VERSION ""

NS_ :

BS_:

BU_:

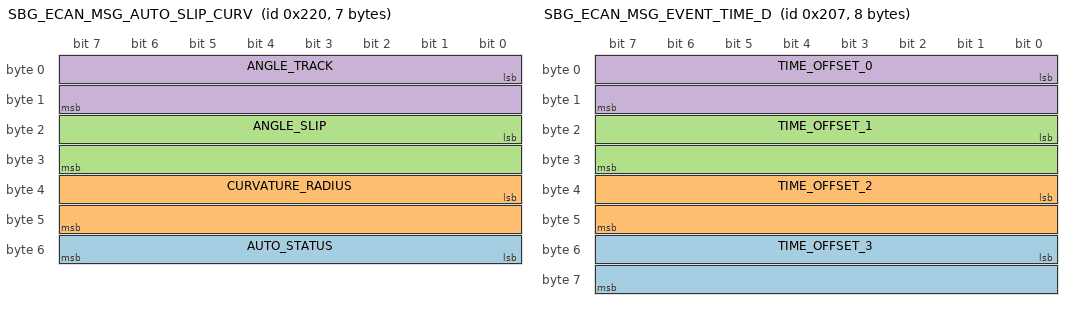
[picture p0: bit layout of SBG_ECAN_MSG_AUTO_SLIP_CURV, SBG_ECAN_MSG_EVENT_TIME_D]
BO_ 544 SBG_ECAN_MSG_AUTO_SLIP_CURV: 7 Vector__XXX
 SG_ AUTO_STATUS : 48|8@1+ (1,0) [0|255] "" Vector__XXX
 SG_ CURVATURE_RADIUS : 32|16@1+ (0.01,0) [0|655.35] "m" Vector__XXX
 SG_ ANGLE_SLIP : 16|16@1- (0.0001,0) [-3.2768|3.2767] "rad" Vector__XXX
 SG_ ANGLE_TRACK : 0|16@1- (0.0001,0) [-3.2768|3.2767] "rad" Vector__XXX

BO_ 519 SBG_ECAN_MSG_EVENT_TIME_D: 8 Vector__XXX
 SG_ TIME_OFFSET_3 : 48|16@1+ (1,0) [0|65535] "µs" Vector__XXX
 SG_ TIME_OFFSET_2 : 32|16@1+ (1,0) [0|65535] "µs" Vector__XXX
 SG_ TIME_OFFSET_1 : 16|16@1+ (1,0) [0|65535] "µs" Vector__XXX
 SG_ TIME_OFFSET_0 : 0|16@1+ (1,0) [0|65535] "µs" Vector__XXX

BO_ 518 SBG_ECAN_MSG_EVENT_INFO_D: 8 Vector__XXX
 SG_ EVENT_STATUS : 32|16@1+ (1,0) [0|65535] "" Vector__XXX
 SG_ TIME_STAMP : 0|32@1+ (1,0) [0|4294970000] "µs" Vector__XXX

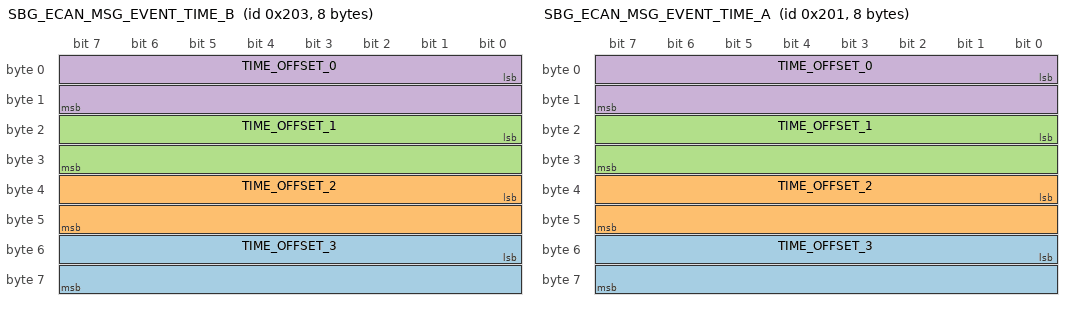
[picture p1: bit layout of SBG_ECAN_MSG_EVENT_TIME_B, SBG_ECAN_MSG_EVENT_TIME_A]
BO_ 515 SBG_ECAN_MSG_EVENT_TIME_B: 8 Vector__XXX
 SG_ TIME_OFFSET_3 : 48|16@1+ (1,0) [0|65535] "µs" Vector__XXX
 SG_ TIME_OFFSET_2 : 32|16@1+ (1,0) [0|65535] "µs" Vector__XXX
 SG_ TIME_OFFSET_1 : 16|16@1+ (1,0) [0|65535] "µs" Vector__XXX
 SG_ TIME_OFFSET_0 : 0|16@1+ (1,0) [0|65535] "µs" Vector__XXX

BO_ 514 SBG_ECAN_MSG_EVENT_INFO_B: 8 Vector__XXX
 SG_ EVENT_STATUS : 32|16@1+ (1,0) [0|65535] "" Vector__XXX
 SG_ TIME_STAMP : 0|32@1+ (1,0) [0|4294970000] "µs" Vector__XXX

BO_ 513 SBG_ECAN_MSG_EVENT_TIME_A: 8 Vector__XXX
 SG_ TIME_OFFSET_3 : 48|16@1+ (1,0) [0|65535] "µs" Vector__XXX
 SG_ TIME_OFFSET_2 : 32|16@1+ (1,0) [0|65535] "µs" Vector__XXX
 SG_ TIME_OFFSET_1 : 16|16@1+ (1,0) [0|65535] "µs" Vector__XXX
 SG_ TIME_OFFSET_0 : 0|16@1+ (1,0) [0|65535] "µs" Vector__XXX

BO_ 512 SBG_ECAN_MSG_EVENT_INFO_A: 8 Vector__XXX
 SG_ EVENT_STATUS : 32|16@1+ (1,0) [0|65535] "" Vector__XXX
 SG_ TIME_STAMP : 0|32@1+ (1,0) [0|4294970000] "µs" Vector__XXX

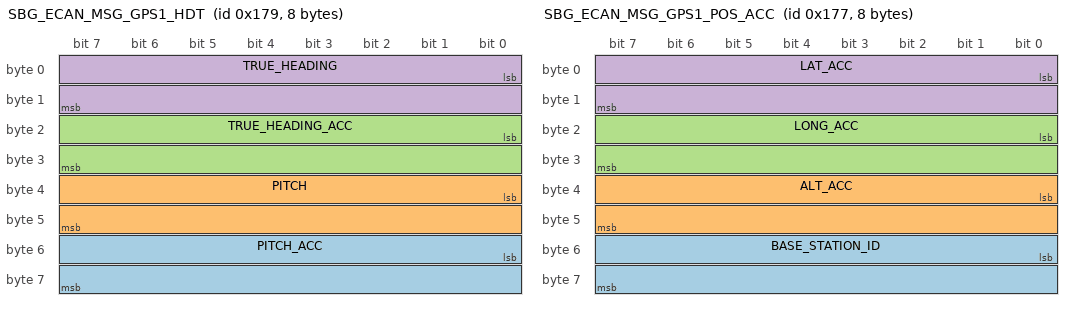
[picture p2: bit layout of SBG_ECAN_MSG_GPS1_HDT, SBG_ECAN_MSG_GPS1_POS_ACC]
BO_ 377 SBG_ECAN_MSG_GPS1_HDT: 8 Vector__XXX
 SG_ PITCH_ACC : 48|16@1+ (0.01,0) [0|655.35] "°" Vector__XXX
 SG_ PITCH : 32|16@1- (0.01,0) [-327.68|327.67] "°" Vector__XXX
 SG_ TRUE_HEADING_ACC : 16|16@1+ (0.01,0) [0|655.35] "°" Vector__XXX
 SG_ TRUE_HEADING : 0|16@1+ (0.01,0) [0|655.35] "°" Vector__XXX

BO_ 376 SBG_ECAN_MSG_GPS1_HDT_INFO: 6 Vector__XXX
 SG_ GPS_HDT_STATUS : 32|16@1+ (1,0) [0|65535] "" Vector__XXX
 SG_ TIME_STAMP : 0|32@1+ (1,0) [0|4294970000] "µs" Vector__XXX

BO_ 375 SBG_ECAN_MSG_GPS1_POS_ACC: 8 Vector__XXX
 SG_ BASE_STATION_ID : 48|16@1+ (1,0) [0|65535] "" Vector__XXX
 SG_ ALT_ACC : 32|16@1+ (0.01,0) [0|655.35] "m" Vector__XXX
 SG_ LONG_ACC : 16|16@1+ (0.01,0) [0|655.35] "m" Vector__XXX
 SG_ LAT_ACC : 0|16@1+ (0.01,0) [0|655.35] "m" Vector__XXX

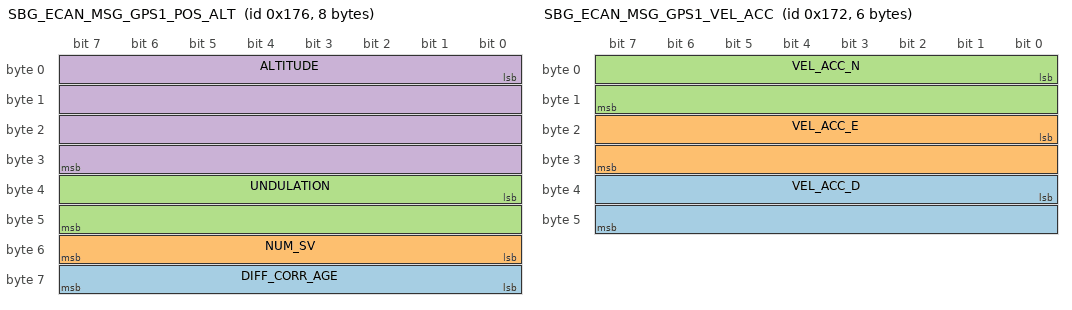
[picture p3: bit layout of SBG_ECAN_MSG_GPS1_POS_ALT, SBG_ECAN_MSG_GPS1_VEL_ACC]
BO_ 374 SBG_ECAN_MSG_GPS1_POS_ALT: 8 Vector__XXX
 SG_ DIFF_CORR_AGE : 56|8@1+ (1,7) [7|262] "s" Vector__XXX
 SG_ NUM_SV : 48|8@1+ (1,48) [48|303] "" Vector__XXX
 SG_ UNDULATION : 32|16@1- (0.005,0) [-163.84|163.835] "m" Vector__XXX
 SG_ ALTITUDE : 0|32@1- (0.001,0) [-2147480|2147480] "m" Vector__XXX

BO_ 373 SBG_ECAN_MSG_GPS1_POS: 8 Vector__XXX
 SG_ LONGITUDE : 32|32@1- (1E-007,0) [-214.7483648|214.7483647] "°" Vector__XXX
 SG_ LATITUDE : 0|32@1- (1E-007,0) [-214.7483648|214.7483647] "°" Vector__XXX

BO_ 372 SBG_ECAN_MSG_GPS1_POS_INFO: 8 Vector__XXX
 SG_ GPS_POS_STATUS : 32|32@1+ (1,0) [0|4294970000] "" Vector__XXX
 SG_ TIME_STAMP : 0|32@1+ (1,0) [0|4294970000] "µs" Vector__XXX

BO_ 371 SBG_ECAN_MSG_GPS1_VEL_COURSE: 4 Vector__XXX
 SG_ COURSE_ACC : 16|16@1+ (0.01,0) [0|655.35] "°" Vector__XXX
 SG_ COURSE : 0|16@1+ (0.01,0) [0|655.35] "°" Vector__XXX

BO_ 370 SBG_ECAN_MSG_GPS1_VEL_ACC: 6 Vector__XXX
 SG_ VEL_ACC_D : 32|16@1- (0.01,0) [-327.68|327.67] "m.s-1" Vector__XXX
 SG_ VEL_ACC_E : 16|16@1- (0.01,0) [-327.68|327.67] "m.s-1" Vector__XXX
 SG_ VEL_ACC_N : 0|16@1- (0.01,0) [-327.68|327.67] "m.s-1" Vector__XXX

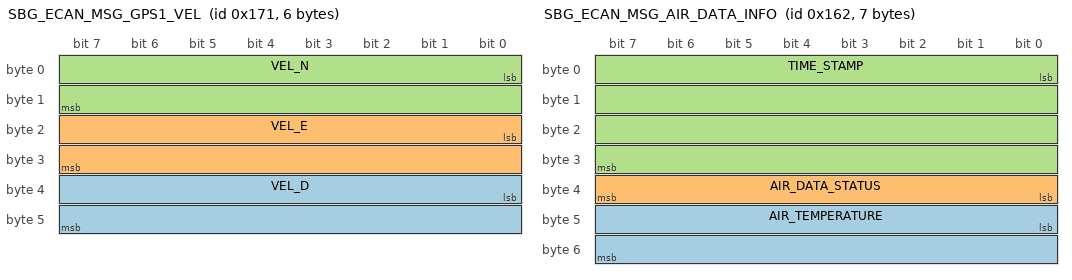
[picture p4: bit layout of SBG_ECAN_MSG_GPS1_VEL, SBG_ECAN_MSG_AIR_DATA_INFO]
BO_ 369 SBG_ECAN_MSG_GPS1_VEL: 6 Vector__XXX
 SG_ VEL_D : 32|16@1- (0.01,0) [-327.68|327.67] "m.s-1" Vector__XXX
 SG_ VEL_E : 16|16@1- (0.01,0) [-327.68|327.67] "m.s-1" Vector__XXX
 SG_ VEL_N : 0|16@1- (0.01,0) [-327.68|327.67] "m.s-1" Vector__XXX

BO_ 368 SBG_ECAN_MSG_GPS1_VEL_INFO: 8 Vector__XXX
 SG_ GPS_VEL_STATUS : 32|32@1+ (1,0) [0|4294970000] "" Vector__XXX
 SG_ TIME_STAMP : 0|32@1+ (1,0) [0|4294970000] "µs" Vector__XXX

BO_ 356 SBG_ECAN_MSG_AIR_DATA_AIRSPEED: 6 Vector__XXX
 SG_ AIRSPEED : 32|16@1- (0.01,0) [-327.68|327.67] "m.s-1" Vector__XXX
 SG_ PRESSURE_DIFF : 0|32@1- (0.001,0) [-2147483.648|2147483.647] "Pa" Vector__XXX

BO_ 355 SBG_ECAN_MSG_AIR_DATA_ALTITUDE: 8 Vector__XXX
 SG_ ALTITUDE : 32|32@1- (0.001,0) [-2147483.648|2147483.647] "m" Vector__XXX
 SG_ PRESSURE_ABS : 0|32@1+ (0.001,0) [0|4294967.295] "Pa" Vector__XXX

BO_ 354 SBG_ECAN_MSG_AIR_DATA_INFO: 7 Vector__XXX
 SG_ AIR_TEMPERATURE : 40|16@1- (0.01,0) [-327.68|327.67] "°C" Vector__XXX
 SG_ AIR_DATA_STATUS : 32|8@1+ (1,0) [0|255] "" Vector__XXX
 SG_ TIME_STAMP : 0|32@1+ (1,0) [0|4294970000] "us" Vector__XXX

BO_ 353 SBG_ECAN_MSG_ODO_VEL: 2 Vector__XXX
 SG_ VELOCITY : 0|16@1- (0.01,0) [-327.68|327.67] "m.s-1" Vector__XXX

BO_ 352 SBG_ECAN_MSG_ODO_INFO: 6 Vector__XXX
 SG_ ODO_STATUS : 32|16@1+ (1,0) [0|65535] "" Vector__XXX
 SG_ TIME_STAMP4 : 0|32@1+ (1,0) [0|4294970000] "µs" Vector__XXX

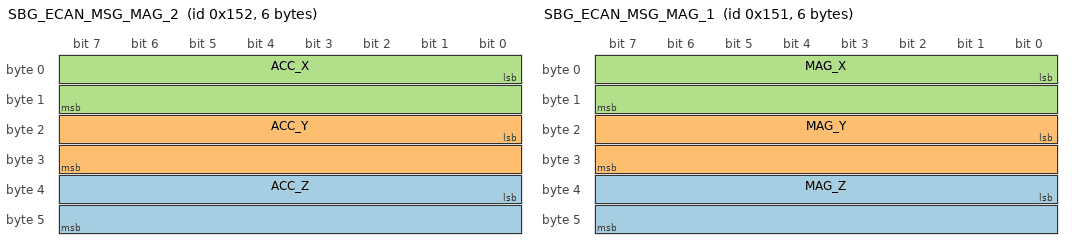
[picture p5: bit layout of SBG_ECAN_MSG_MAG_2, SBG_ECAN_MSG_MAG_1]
BO_ 338 SBG_ECAN_MSG_MAG_2: 6 Vector__XXX
 SG_ ACC_Z : 32|16@1- (0.01,0) [-327.68|327.67] "m.s-2" Vector__XXX
 SG_ ACC_Y : 16|16@1- (0.01,0) [-327.68|327.67] "m.s-2" Vector__XXX
 SG_ ACC_X : 0|16@1- (0.01,0) [-327.68|327.67] "m.s-2" Vector__XXX

BO_ 337 SBG_ECAN_MSG_MAG_1: 6 Vector__XXX
 SG_ MAG_Z : 32|16@1- (0.001,0) [-32.768|32.767] "a.u." Vector__XXX
 SG_ MAG_Y : 16|16@1- (0.001,0) [-32.768|32.767] "a.u." Vector__XXX
 SG_ MAG_X : 0|16@1- (0.001,0) [-32.768|32.767] "a.u." Vector__XXX

BO_ 336 SBG_ECAN_MSG_MAG_0: 6 Vector__XXX
 SG_ MAG_STATUS : 32|16@1+ (1,0) [0|65535] "" Vector__XXX
 SG_ TIME_STAMP : 0|32@1+ (1,0) [0|4294970000] "µs" Vector__XXX

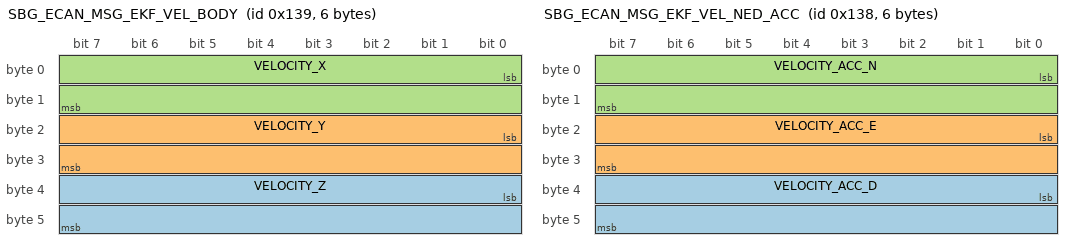
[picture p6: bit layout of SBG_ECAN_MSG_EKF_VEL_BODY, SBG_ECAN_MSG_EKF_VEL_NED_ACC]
BO_ 313 SBG_ECAN_MSG_EKF_VEL_BODY: 6 Vector__XXX
 SG_ VELOCITY_Z : 32|16@1- (0.01,0) [-327.68|327.67] "m.s-1" Vector__XXX
 SG_ VELOCITY_Y : 16|16@1- (0.01,0) [-327.68|327.67] "m.s-1" Vector__XXX
 SG_ VELOCITY_X : 0|16@1- (0.01,0) [-327.68|327.67] "m.s-1" Vector__XXX

BO_ 312 SBG_ECAN_MSG_EKF_VEL_NED_ACC: 6 Vector__XXX
 SG_ VELOCITY_ACC_D : 32|16@1- (0.01,0) [-327.68|327.67] "m.s-1" Vector__XXX
 SG_ VELOCITY_ACC_E : 16|16@1- (0.01,0) [-327.68|327.67] "m.s-1" Vector__XXX
 SG_ VELOCITY_ACC_N : 0|16@1- (0.01,0) [-327.68|327.67] "m.s-1" Vector__XXX

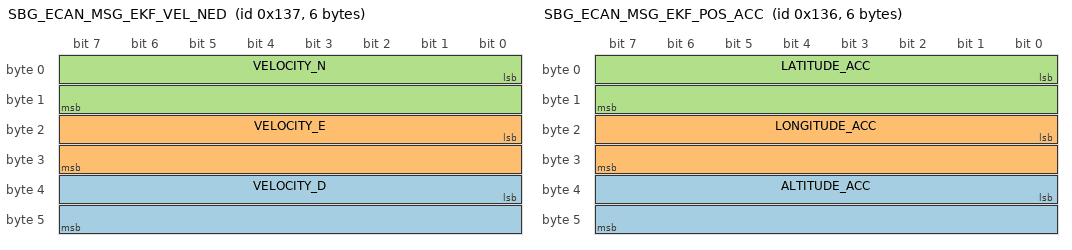
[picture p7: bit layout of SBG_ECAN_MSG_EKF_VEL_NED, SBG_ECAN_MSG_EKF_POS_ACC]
BO_ 311 SBG_ECAN_MSG_EKF_VEL_NED: 6 Vector__XXX
 SG_ VELOCITY_D : 32|16@1- (0.01,0) [-327.68|327.67] "m.s-1" Vector__XXX
 SG_ VELOCITY_E : 16|16@1- (0.01,0) [-327.68|327.67] "m.s-1" Vector__XXX
 SG_ VELOCITY_N : 0|16@1- (0.01,0) [-327.68|327.67] "m.s-1" Vector__XXX

BO_ 310 SBG_ECAN_MSG_EKF_POS_ACC: 6 Vector__XXX
 SG_ ALTITUDE_ACC : 32|16@1+ (0.01,0) [0|655.35] "m" Vector__XXX
 SG_ LONGITUDE_ACC : 16|16@1+ (0.01,0) [0|655.35] "m" Vector__XXX
 SG_ LATITUDE_ACC : 0|16@1+ (0.01,0) [0|655.35] "m" Vector__XXX

BO_ 309 SBG_ECAN_MSG_EKF_ALTITUDE: 6 Vector__XXX
 SG_ UNDULATION : 32|16@1- (0.005,0) [-163.84|163.835] "m" Vector__XXX
 SG_ ALTITUDE : 0|32@1- (0.001,0) [-2147480|2147480] "m" Vector__XXX

BO_ 308 SBG_ECAN_MSG_EKF_POS: 8 Vector__XXX
 SG_ LONGITUDE : 32|32@1- (1E-007,0) [-214.7483648|214.7483647] "°" Vector__XXX
 SG_ LATITUDE : 0|32@1- (1E-007,0) [-214.7483648|214.7483647] "°" Vector__XXX

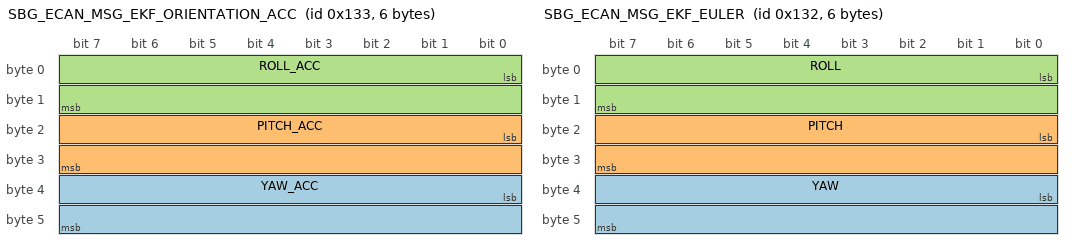
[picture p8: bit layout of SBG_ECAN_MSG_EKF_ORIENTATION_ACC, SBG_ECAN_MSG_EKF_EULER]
BO_ 307 SBG_ECAN_MSG_EKF_ORIENTATION_ACC: 6 Vector__XXX
 SG_ YAW_ACC : 32|16@1+ (0.0001,0) [0|6.5535] "rad" Vector__XXX
 SG_ PITCH_ACC : 16|16@1+ (0.0001,0) [0|6.5535] "rad" Vector__XXX
 SG_ ROLL_ACC : 0|16@1+ (0.0001,0) [0|6.5535] "rad" Vector__XXX

BO_ 306 SBG_ECAN_MSG_EKF_EULER: 6 Vector__XXX
 SG_ YAW : 32|16@1- (0.0001,0) [-3.2768|3.2767] "rad" Vector__XXX
 SG_ PITCH : 16|16@1- (0.0001,0) [-3.2768|3.2767] "rad" Vector__XXX
 SG_ ROLL : 0|16@1- (0.0001,0) [-3.2768|3.2767] "rad" Vector__XXX

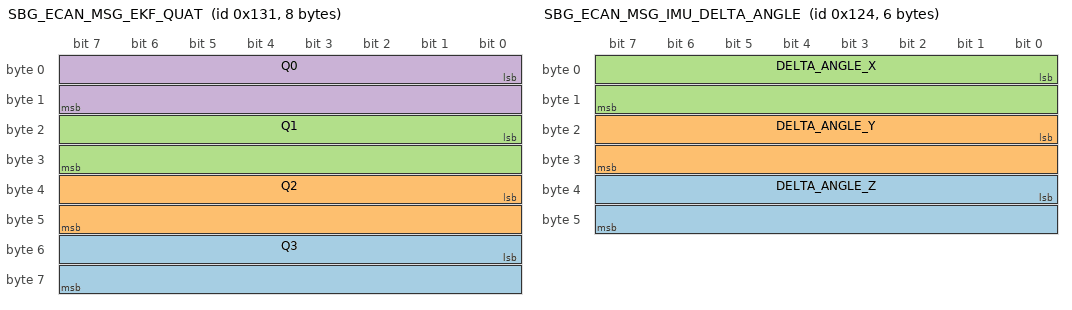
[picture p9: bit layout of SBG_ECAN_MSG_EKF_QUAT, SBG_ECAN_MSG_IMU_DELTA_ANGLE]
BO_ 305 SBG_ECAN_MSG_EKF_QUAT: 8 Vector__XXX
 SG_ Q3 : 48|16@1- (3.05185094759972E-005,0) [-1|1] "" Vector__XXX
 SG_ Q2 : 32|16@1- (3.05185094759972E-005,0) [-1|1] "" Vector__XXX
 SG_ Q1 : 16|16@1- (3.05185094759972E-005,0) [-1|1] "" Vector__XXX
 SG_ Q0 : 0|16@1- (3.05185094759972E-005,0) [-1|1] "" Vector__XXX

BO_ 304 SBG_ECAN_MSG_EKF_INFO: 4 Vector__XXX
 SG_ TIME_STAMP : 0|32@1+ (1,0) [0|4294970000] "µs" Vector__XXX

BO_ 292 SBG_ECAN_MSG_IMU_DELTA_ANGLE: 6 Vector__XXX
 SG_ DELTA_ANGLE_Z : 32|16@1- (0.001,0) [-32.768|32.767] "rad.s-1" Vector__XXX
 SG_ DELTA_ANGLE_Y : 16|16@1- (0.001,0) [-32.768|32.767] "rad.s-1" Vector__XXX
 SG_ DELTA_ANGLE_X : 0|16@1- (0.001,0) [-32.768|32.767] "rad.s-1" Vector__XXX

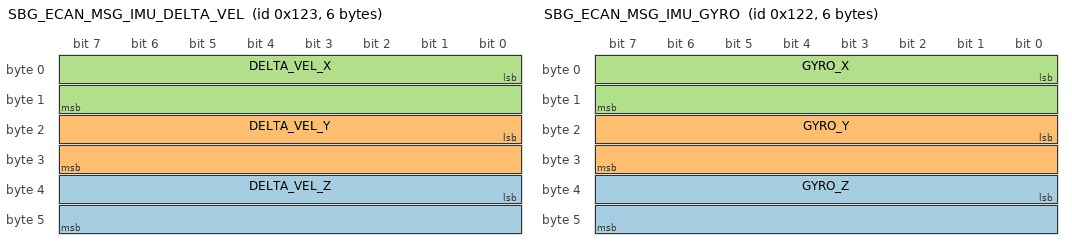
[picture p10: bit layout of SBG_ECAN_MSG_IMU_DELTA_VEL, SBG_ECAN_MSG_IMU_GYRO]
BO_ 291 SBG_ECAN_MSG_IMU_DELTA_VEL: 6 Vector__XXX
 SG_ DELTA_VEL_Z : 32|16@1- (0.01,0) [-327.68|327.67] "m.s-2" Vector__XXX
 SG_ DELTA_VEL_Y : 16|16@1- (0.01,0) [-327.68|327.67] "m.s-2" Vector__XXX
 SG_ DELTA_VEL_X : 0|16@1- (0.01,0) [-327.68|327.67] "m.s-2" Vector__XXX

BO_ 290 SBG_ECAN_MSG_IMU_GYRO: 6 Vector__XXX
 SG_ GYRO_Z : 32|16@1- (0.001,0) [-32.768|32.767] "rad.s-1" Vector__XXX
 SG_ GYRO_Y : 16|16@1- (0.001,0) [-32.768|32.767] "rad.s-1" Vector__XXX
 SG_ GYRO_X : 0|16@1- (0.001,0) [-32.768|32.767] "rad.s-1" Vector__XXX

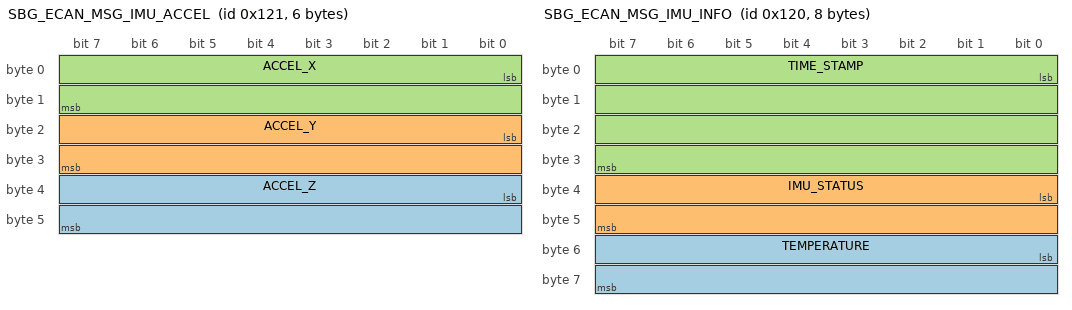
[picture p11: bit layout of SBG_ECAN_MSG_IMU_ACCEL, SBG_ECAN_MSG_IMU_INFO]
BO_ 289 SBG_ECAN_MSG_IMU_ACCEL: 6 Vector__XXX
 SG_ ACCEL_Z : 32|16@1- (0.01,0) [-327.68|327.67] "m.s-2" Vector__XXX
 SG_ ACCEL_Y : 16|16@1- (0.01,0) [-327.68|327.67] "m.s-2" Vector__XXX
 SG_ ACCEL_X : 0|16@1- (0.01,0) [-327.68|327.67] "m.s-2" Vector__XXX

BO_ 288 SBG_ECAN_MSG_IMU_INFO: 8 Vector__XXX
 SG_ TEMPERATURE : 48|16@1- (0.01,0) [-327.68|327.67] "°C" Vector__XXX
 SG_ IMU_STATUS : 32|16@1+ (1,0) [0|65535] "" Vector__XXX
 SG_ TIME_STAMP : 0|32@1+ (1,0) [0|4294970000] "µs" Vector__XXX

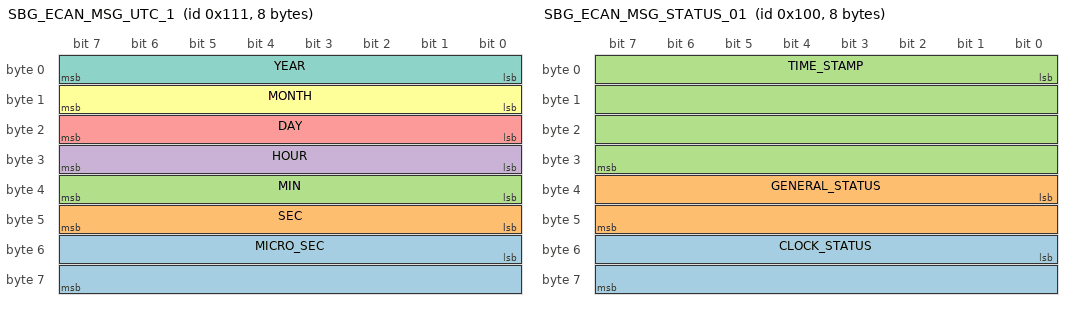
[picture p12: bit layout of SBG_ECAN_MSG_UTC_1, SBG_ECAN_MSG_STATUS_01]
BO_ 273 SBG_ECAN_MSG_UTC_1: 8 Vector__XXX
 SG_ MICRO_SEC : 48|16@1+ (100,0) [0|6553500] "us" Vector__XXX
 SG_ SEC : 40|8@1+ (1,0) [0|255] "s" Vector__XXX
 SG_ MIN : 32|8@1+ (1,0) [0|255] "min" Vector__XXX
 SG_ HOUR : 24|8@1+ (1,0) [0|255] "h" Vector__XXX
 SG_ DAY : 16|8@1+ (1,0) [0|255] "d" Vector__XXX
 SG_ MONTH : 8|8@1+ (1,0) [0|255] "month" Vector__XXX
 SG_ YEAR : 0|8@1+ (1,2000) [2000|2255] "year" Vector__XXX

BO_ 272 SBG_ECAN_MSG_UTC_0: 8 Vector__XXX
 SG_ GPS_TOW : 32|32@1+ (1,0) [0|4294970000] "ms" Vector__XXX
 SG_ TIME_STAMP : 0|32@1+ (1,0) [0|4294970000] "µs" Vector__XXX

BO_ 258 SBG_ECAN_MSG_STATUS_03: 6 Vector__XXX
 SG_ HEAVE_STATUS : 32|16@1+ (1,0) [0|65535] "" Vector__XXX
 SG_ SOLUTION_STATUS : 0|32@1+ (1,0) [0|4294970000] "" Vector__XXX

BO_ 257 SBG_ECAN_MSG_STATUS_02: 8 Vector__XXX
 SG_ AIDING_STATUS : 32|32@1+ (1,0) [0|4294970000] "" Vector__XXX
 SG_ COM_STATUS : 0|32@1+ (1,0) [0|4294970000] "" Vector__XXX

BO_ 256 SBG_ECAN_MSG_STATUS_01: 8 Vector__XXX
 SG_ CLOCK_STATUS : 48|16@1+ (1,0) [0|65535] "" Vector__XXX
 SG_ GENERAL_STATUS : 32|16@1+ (1,0) [0|65535] "" Vector__XXX
 SG_ TIME_STAMP : 0|32@1+ (1,0) [0|4294970000] "µs" Vector__XXX
